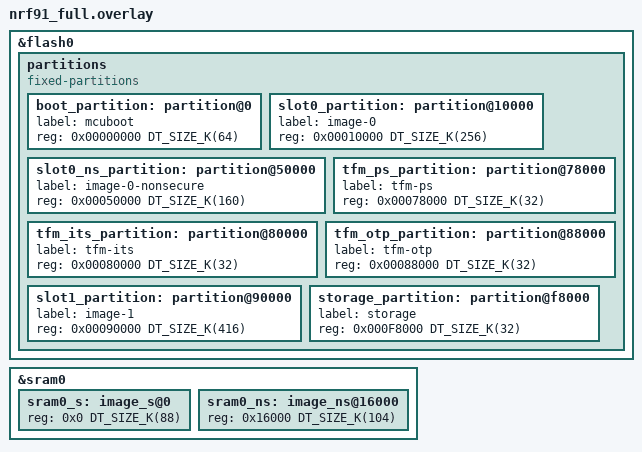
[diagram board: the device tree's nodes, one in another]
/*
 * Copyright (c) 2026 Nordic Semiconductor ASA
 *
 * SPDX-License-Identifier: LicenseRef-Nordic-5-Clause
 */

/*
 * Full-featured TF-M partition layout with MCUboot for nRF91 Series
 *
 * nRF91 Series has 1024 kB of flash and 256 kB of SRAM.
 * TrustZone flash region alignment: 32 kB (SPU-based)
 * TrustZone RAM region alignment:    8 kB
 * Flash erase-block-size:            4 kB
 *
 * This layout enables all TF-M services with MCUboot:
 * - MCUboot bootloader
 * - Primary and secondary slots for FOTA
 * - Full TF-M profile with PS, ITS, OTP
 * - Non-secure storage for application
 *
 * Suitable for: full-featured cellular IoT devices, asset trackers
 *
 * Applies to boards: nrf9160dk/nrf9160/ns, nrf9161dk/nrf9161/ns,
 *                    nrf9151dk/nrf9151/ns
 */

&flash0 {
	partitions {
		compatible = "fixed-partitions";
		#address-cells = <1>;
		#size-cells = <1>;

		/*
		 * Flash layout (S/NS boundaries 32 kB aligned):
		 *
		 * 0x00000000  MCUboot bootloader        (64 kB = 2 × 32 kB)
		 * 0x00010000  Primary slot:
		 *   0x00010000  TF-M secure image       (256 kB = 8 × 32 kB)
		 *   0x00050000  Non-secure application   (160 kB = 5 × 32 kB)
		 * 0x00078000  TF-M PS                    (32 kB = 1 × 32 kB)
		 * 0x00080000  TF-M ITS                   (32 kB = 1 × 32 kB)
		 * 0x00088000  TF-M OTP / NV counters     (32 kB = 1 × 32 kB)
		 * 0x00090000  Secondary slot            (416 kB)
		 * 0x000F8000  Non-secure storage         (32 kB)
		 *
		 * Primary slot total = 256 + 160 = 416 kB = Secondary slot
		 * S/NS boundary at 0x50000 is 32 kB aligned.
		 */

		boot_partition: partition@0 {
			label = "mcuboot";
			reg = <0x00000000 DT_SIZE_K(64)>;
		};

		slot0_partition: partition@10000 {
			label = "image-0";
			reg = <0x00010000 DT_SIZE_K(256)>;
		};

		slot0_ns_partition: partition@50000 {
			label = "image-0-nonsecure";
			reg = <0x00050000 DT_SIZE_K(160)>;
		};

		tfm_ps_partition: partition@78000 {
			label = "tfm-ps";
			reg = <0x00078000 DT_SIZE_K(32)>;
		};

		tfm_its_partition: partition@80000 {
			label = "tfm-its";
			reg = <0x00080000 DT_SIZE_K(32)>;
		};

		tfm_otp_partition: partition@88000 {
			label = "tfm-otp";
			reg = <0x00088000 DT_SIZE_K(32)>;
		};

		slot1_partition: partition@90000 {
			label = "image-1";
			reg = <0x00090000 DT_SIZE_K(416)>;
		};

		storage_partition: partition@f8000 {
			label = "storage";
			reg = <0x000F8000 DT_SIZE_K(32)>;
		};
	};
};

&sram0 {
	sram0_s: image_s@0 {
		#address-cells = <1>;
		#size-cells = <1>;
		/* 88 kB secure — 8 kB aligned */
		reg = <0x0 DT_SIZE_K(88)>;
		ranges = <0x0 0x0 DT_SIZE_K(88)>;
	};

	sram0_ns: image_ns@16000 {
		#address-cells = <1>;
		#size-cells = <1>;
		/* 104 kB non-secure — sufficient for LTE + app */
		reg = <0x16000 DT_SIZE_K(104)>;
		ranges = <0x0 0x16000 DT_SIZE_K(104)>;
	};
};
